# MCU_FSS0_HPB_CTRL register map
Vendor: Texas Instruments
Peripheral module from a debugger description file (folder am65x).
Registers are 32-bit, access per field, reset 0x0 unless marked. A register's access mark holds for its fields unless they carry their own. Offsets are as the file gives them; lines under a group give offsets from that group; [hi:lo] are bit positions; {n}, {i} and the like mark numbered series; 'fields as' and 'values as' point back to an identical list; <NAME> marks a mode.

## MCU_FSS0_HPB_CTRL
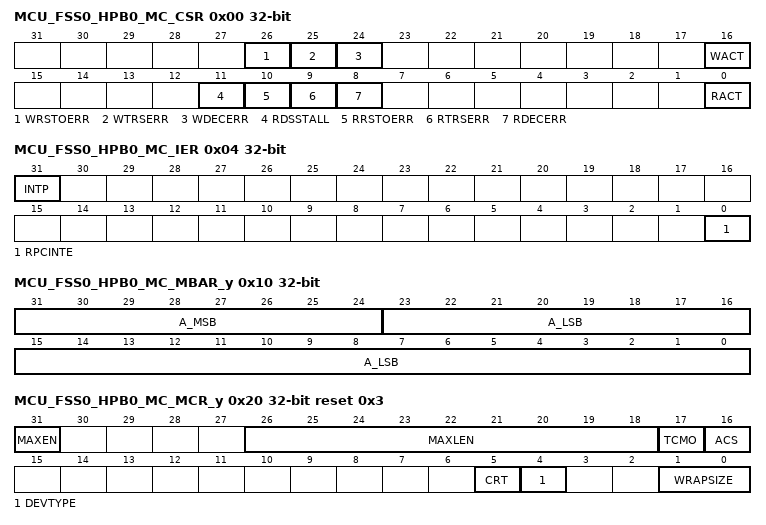
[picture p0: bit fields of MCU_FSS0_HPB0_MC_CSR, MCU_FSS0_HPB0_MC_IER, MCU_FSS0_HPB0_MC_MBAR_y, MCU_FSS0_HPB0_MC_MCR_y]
0x00 MCU_FSS0_HPB0_MC_CSR ro — Controller Status Register The Controller Status Register is used to access the internal status of the HBMC.
  [26] WRSTOERR — Write RSTO Error This bit indicates whether HyperBus memory is under reset state in the latest write operation. When this bit is set, HBMC responds by AXI SLVERR. 0h = Normal operation 1h = HyperBus memory is under reset
  [25] WTRSERR — Write Transaction Error This bit indicates whether AXI protocol is acceptable by HBMC in the latest write transaction. When this bit is set, HBMC responds by AXI SLVERR. 0h = Normal operation 1h = This protocol is not supported
  [24] WDECERR — Write Decode Error This bit indicates whether access address is acceptable in the latest write transaction. When this bit is set, HBMC responds by AXI DECERR. 0h = Normal operation 1h = Access address is not reachable
  [16] WACT — Write Active This bit indicates whether write transaction is in progress or not. When receiving write request on write address channel, this bit becomes 1h. When retrieving response signaling on write response channel, this bit becomes 0h. 0h = Write is idle 1h = Write is active
  [11] RDSSTALL — RDS Stall This bit indicates whether read data transfer from HyperBus memory is stalled (RDS Stall remains LOW) in the latest read transaction. When this bit is set, HBMC responds by AXI SLVERR. 0h = Normal operation 1h = RDS is stalled
  [10] RRSTOERR — Read RSTO Error This bit indicates whether HyperBus memory is under reset state in the latest read operation. When this bit is set, HBMC responds by AXI SLVERR. 0h = Normal operation 1h = HyperBus memory is under reset
  [9] RTRSERR — Read Transaction Error This bit indicates whether AXI protocol is acceptable by HBMC in the latest read transaction. When this bit is set, HBMC responds by AXI SLVERR. 0h = Normal operation 1h = This protocol is not supported
  [8] RDECERR — Read Decode Error This bit indicates whether access address is acceptable in the latest read transaction. When this bit is set, HBMC responds by AXI DECERR. 0h = Normal operation 1h = Access address is not reachable
  [0] RACT — Read Active This bit indicates whether read transaction is in progress or not. When receiving read request on read address channel, this bit becomes 1h. When retrieving all requested data on read data channel, this bit becomes 0h. 0h = Read is idle 1h = Read is active
0x04 MCU_FSS0_HPB0_MC_IER — Interrupt Enable Register The HBMC outputs optional interrupt signal by condition enabled by the Interrupt Enable Register.
  [31] INTP rw — Interrupt Polarity Control This bit is used to choose the polarity of optional interrupt signal (IENOn). 0h = IENOn signal is active low 1h = IENOn signal is active high (Reversed mode)
  [0] RPCINTE rw — HyperBus Memory Interrupt Enable 0h = Disable interrupt 1h = Enable interrupt by INT# signal of HyperBus memory
0x08 MCU_FSS0_HPB0_MC_ISR ro — Interrupt Status Register The Interrupt Status Register is used to read the status for the interrupts generated.
  [0] RPCINTS — HyperBus Memory Interrupt 0h = No interrupt 1h = This bit displays interrupt from INT# signal of HyperBus memory
0x10 MCU_FSS0_HPB0_MC_MBAR_y — Memory Base Address Register for device connected to CS# The base address of addressable region to Hyperflash memory can be set-up using this register. The controller can't assert two chip selects CS0# and CS1# at a time. Hence this register describes how to select chip select. Offset = 10h + (y × 4h); where y = 0h to 1h
  [31:24] A_MSB rw — MSB 8 bit of the base address of addressable region to HyperBus memory
  [23:0] A_LSB ro — Since register can be set in 16 MB boundary, lower 24 bit is fixed to 0h, if read, this field will always return 0h.
0x20 MCU_FSS0_HPB0_MC_MCR_y reset 0x3 — Memory Configuration Register for CS# Offset = 20h + (y × 4h); where y = 0h to 1h
  [31] MAXEN rw — Maximum Length Enable When this bit is set to 1h, CS# low time can be configurable by MAXLEN bit. 0h = No configurable CS# low time 1h = Configurable CS# low time
  [26:18] MAXLEN rw — Maximum Length This bit indicates maximum read/write transaction length to memory. This bit is ignored when MAXEN bit is 0h. 0h = 2 Byte (1 HyperBus CK) 1h = 4 Byte (2 HyperBus CK) 2h = 6 Byte (3 HyperBus CK) .... 1FFh = 1024 Byte (512 HyperBus CK)
  [17] TCMO rw — True Continuous Merge Option Note that this function can be used with the HyperFlash with specific function. Please confirm whether it is available on the corresponding HyperFlash before enabling this function. When HyperBus memory doesn't accept the 8-bit boundary address, and a wrapping burst access with ARSIZE = 0h and ARADDR0 = 1h is used, this bit must not be set to 1h. 0h = No merging WRAP and INCR 1h = Merging WRAP and INCR
  [16] ACS rw — Asymmetry Cache Support This function should be disabled if the HyperBus memory itself supports the asymmetry cache system. 0h = No asymmetry cache system support 1h = Asymmetry cache system support
  [5] CRT rw — Configuration Register Target This bit indicates whether the read or write operation accesses the memory or CR space. This bit is mapped to CA-46 bit in HyperRAM. When using HyperFlash, this bit should be set to 0h. 0h = Memory space 1h = CR space
  [4] DEVTYPE rw — Device Type Device type for control target. 0h = HyperFlash 1h = HyperRAM
  [1:0] WRAPSIZE rw — Wrap Size The wrap burst length of HyperBus memory. This bit is ignored when the asymmetry cache support bit is 0h. When the asymmetry cache support is 1h, this bit should be set the same as wrap size of configuration register in HyperBus memory. 0h = Reserved 1h = 64 Bytes 2h = 16 Bytes 3h = 32 Bytes
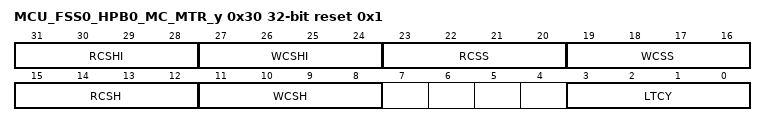
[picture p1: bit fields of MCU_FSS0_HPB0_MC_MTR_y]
0x30 MCU_FSS0_HPB0_MC_MTR_y reset 0x1 — Memory Timing Register Memory access timings for CS# can be configured using the Memory Timing Register. Offset = 30h + (y × 4h); where y = 0h to 1h
  [31:28] RCSHI rw — Read Chip Select High Between Operations This bit indicates CS# high time for read between operations. 0h = corresponds to 1.5 clock cycle Fh = corresponds to 16.5 clock cycle
  [27:24] WCSHI rw — Write Chip Select High Between Operations This bit indicates CS# high time for write between operations. 0h = corresponds to 1.5 clock cycle Fh = corresponds to 16.5 clock cycle
  [23:20] RCSS rw — Read Chip Select Setup to next CK rising edge This bit indicates CS# setup time for read from CS# assertion. 0h = corresponds to 1 clock cycle Fh = corresponds to 16 clock cycle
  [19:16] WCSS rw — Write Chip Select Setup to next CK rising edge This bit indicates CS# setup time for write from CS# assertion. 0h = corresponds to 1 clock cycle Fh = corresponds to 16 clock cycle
  [15:12] RCSH rw — Read Chip Select Hold after CK falling edge This bit indicates CS# hold time for read to CS# de-assertion. 0h = corresponds to 1 clock cycle Fh = corresponds to 16 clock cycle
  [11:8] WCSH rw — Write Chip Select Hold after CK falling edge This bit indicates CS# hold time for write to CS# de-assertion. 0h = corresponds to 1 clock cycle Fh = corresponding to 16 clock cycle
  [3:0] LTCY rw — Latency Cycle Only uses in HyperRAM This bit indicates initial latency code for read/write access. This bit is ignored when the 0h = 5 clock latency 1h = 6 clock latency 2h = Reserved .... Dh = Reserved Eh = 3 clock latency Fh = 4 clock latency
0x40 MCU_FSS0_HPB0_MC_GPOR — General Purpose Output Register Output signal polarity can be configured using the General Purpose Output Register. General Purpose Output register () of the HBMC is not used (see , HyperBus Not Supported Features).
  [1:0] GPO rw — General Purpose Output Interface 0h = Output signal polarity is LOW 1h = Output signal polarity is HIGH
0x44 MCU_FSS0_HPB0_MC_WPR — Write Protection Register Write protection can be configured using the Write Protection Register. WPn pin is not used on Cypress flash devices (see ).
  [0] WP rw — Write Protection Control 0h = Not Protected WP# signal is HIGH 1h = Protected WP# signal is LOW
0x48 MCU_FSS0_HPB0_MC_LBR — Loop Back Register Loopback settings can be configured using the Loop Back Register.
  [0] LOOPBACK rw — The write transaction data written on AXI bus is looped back as the read data from RPC bus. The loop-back is performed between WDAT FIFO and RDAT FIFO in AXI interface controller. 0h = Disable loopback 1h = Enable loopback
